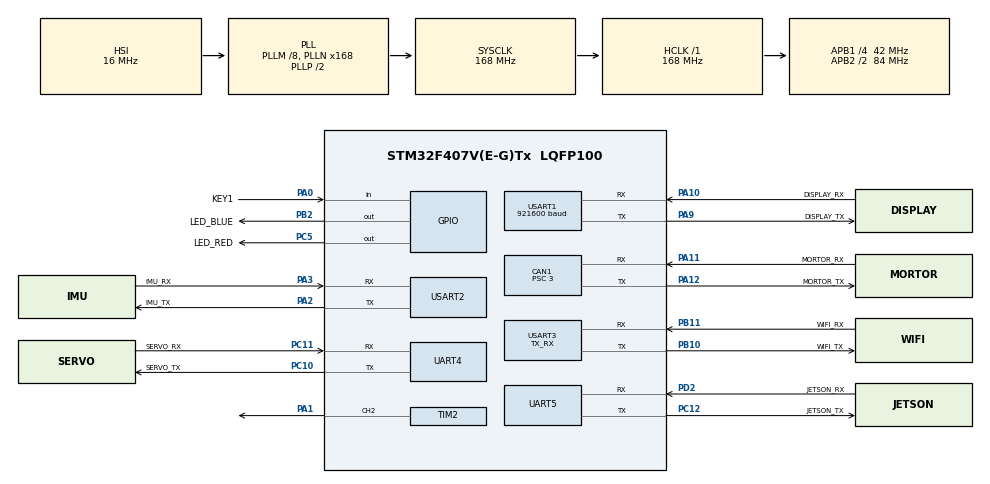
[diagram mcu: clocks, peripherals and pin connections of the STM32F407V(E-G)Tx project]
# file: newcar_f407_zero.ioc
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CAN1.ABOM=DISABLE
CAN1.AWUM=ENABLE
CAN1.BS1=CAN_BS1_7TQ
CAN1.BS2=CAN_BS2_6TQ
CAN1.CalculateBaudRate=1000000
CAN1.CalculateTimeBit=1000
CAN1.CalculateTimeQuantum=71.42857142857143
CAN1.NART=DISABLE
CAN1.Prescaler=3
Dma.MEMTOMEM.0.Direction=DMA_MEMORY_TO_MEMORY
Dma.MEMTOMEM.0.FIFOMode=DMA_FIFOMODE_ENABLE
Dma.MEMTOMEM.0.FIFOThreshold=DMA_FIFO_THRESHOLD_FULL
Dma.MEMTOMEM.0.Instance=DMA2_Stream0
Dma.MEMTOMEM.0.MemBurst=DMA_MBURST_SINGLE
Dma.MEMTOMEM.0.MemDataAlignment=DMA_MDATAALIGN_BYTE
Dma.MEMTOMEM.0.MemInc=DMA_MINC_ENABLE
Dma.MEMTOMEM.0.Mode=DMA_NORMAL
Dma.MEMTOMEM.0.PeriphBurst=DMA_PBURST_SINGLE
Dma.MEMTOMEM.0.PeriphDataAlignment=DMA_PDATAALIGN_BYTE
Dma.MEMTOMEM.0.PeriphInc=DMA_PINC_ENABLE
Dma.MEMTOMEM.0.Priority=DMA_PRIORITY_LOW
Dma.Request0=MEMTOMEM
Dma.Request1=USART1_TX
Dma.Request10=USART1_RX
Dma.Request2=USART2_RX
Dma.Request3=USART2_TX
Dma.Request4=UART4_RX
Dma.Request5=UART4_TX
Dma.Request6=UART5_RX
Dma.Request7=UART5_TX
Dma.Request8=USART3_RX
Dma.Request9=USART3_TX
Dma.UART4_RX.4.Direction=DMA_PERIPH_TO_MEMORY
Dma.UART4_RX.4.FIFOMode=DMA_FIFOMODE_ENABLE
Dma.UART4_RX.4.FIFOThreshold=DMA_FIFO_THRESHOLD_FULL
Dma.UART4_RX.4.Instance=DMA1_Stream2
Dma.UART4_RX.4.MemBurst=DMA_MBURST_SINGLE
Dma.UART4_RX.4.MemDataAlignment=DMA_MDATAALIGN_BYTE
Dma.UART4_RX.4.MemInc=DMA_MINC_ENABLE
Dma.UART4_RX.4.Mode=DMA_NORMAL
Dma.UART4_RX.4.PeriphBurst=DMA_PBURST_SINGLE
Dma.UART4_RX.4.PeriphDataAlignment=DMA_PDATAALIGN_BYTE
Dma.UART4_RX.4.PeriphInc=DMA_PINC_DISABLE
Dma.UART4_RX.4.Priority=DMA_PRIORITY_LOW
Dma.UART4_TX.5.Direction=DMA_MEMORY_TO_PERIPH
Dma.UART4_TX.5.FIFOMode=DMA_FIFOMODE_ENABLE
Dma.UART4_TX.5.FIFOThreshold=DMA_FIFO_THRESHOLD_FULL
Dma.UART4_TX.5.Instance=DMA1_Stream4
Dma.UART4_TX.5.MemBurst=DMA_MBURST_SINGLE
Dma.UART4_TX.5.MemDataAlignment=DMA_MDATAALIGN_BYTE
Dma.UART4_TX.5.MemInc=DMA_MINC_ENABLE
Dma.UART4_TX.5.Mode=DMA_NORMAL
Dma.UART4_TX.5.PeriphBurst=DMA_PBURST_SINGLE
Dma.UART4_TX.5.PeriphDataAlignment=DMA_PDATAALIGN_BYTE
Dma.UART4_TX.5.PeriphInc=DMA_PINC_DISABLE
Dma.UART4_TX.5.Priority=DMA_PRIORITY_LOW
Dma.UART5_RX.6.Direction=DMA_PERIPH_TO_MEMORY
Dma.UART5_RX.6.FIFOMode=DMA_FIFOMODE_ENABLE
Dma.UART5_RX.6.FIFOThreshold=DMA_FIFO_THRESHOLD_FULL
Dma.UART5_RX.6.Instance=DMA1_Stream0
Dma.UART5_RX.6.MemBurst=DMA_MBURST_SINGLE
Dma.UART5_RX.6.MemDataAlignment=DMA_MDATAALIGN_BYTE
Dma.UART5_RX.6.MemInc=DMA_MINC_ENABLE
Dma.UART5_RX.6.Mode=DMA_NORMAL
Dma.UART5_RX.6.PeriphBurst=DMA_PBURST_SINGLE
Dma.UART5_RX.6.PeriphDataAlignment=DMA_PDATAALIGN_BYTE
Dma.UART5_RX.6.PeriphInc=DMA_PINC_DISABLE
Dma.UART5_RX.6.Priority=DMA_PRIORITY_VERY_HIGH
Dma.UART5_TX.7.Direction=DMA_MEMORY_TO_PERIPH
Dma.UART5_TX.7.FIFOMode=DMA_FIFOMODE_ENABLE
Dma.UART5_TX.7.FIFOThreshold=DMA_FIFO_THRESHOLD_FULL
Dma.UART5_TX.7.Instance=DMA1_Stream7
Dma.UART5_TX.7.MemBurst=DMA_MBURST_SINGLE
Dma.UART5_TX.7.MemDataAlignment=DMA_MDATAALIGN_BYTE
Dma.UART5_TX.7.MemInc=DMA_MINC_ENABLE
Dma.UART5_TX.7.Mode=DMA_NORMAL
Dma.UART5_TX.7.PeriphBurst=DMA_PBURST_SINGLE
Dma.UART5_TX.7.PeriphDataAlignment=DMA_PDATAALIGN_BYTE
Dma.UART5_TX.7.PeriphInc=DMA_PINC_DISABLE
Dma.UART5_TX.7.Priority=DMA_PRIORITY_VERY_HIGH
Dma.USART1_RX.10.Direction=DMA_PERIPH_TO_MEMORY
Dma.USART1_RX.10.FIFOMode=DMA_FIFOMODE_ENABLE
Dma.USART1_RX.10.FIFOThreshold=DMA_FIFO_THRESHOLD_FULL
Dma.USART1_RX.10.Instance=DMA2_Stream2
Dma.USART1_RX.10.MemBurst=DMA_MBURST_SINGLE
Dma.USART1_RX.10.MemDataAlignment=DMA_MDATAALIGN_BYTE
Dma.USART1_RX.10.MemInc=DMA_MINC_ENABLE
Dma.USART1_RX.10.Mode=DMA_NORMAL
Dma.USART1_RX.10.PeriphBurst=DMA_PBURST_SINGLE
Dma.USART1_RX.10.PeriphDataAlignment=DMA_PDATAALIGN_BYTE
Dma.USART1_RX.10.PeriphInc=DMA_PINC_DISABLE
Dma.USART1_RX.10.Priority=DMA_PRIORITY_VERY_HIGH
Dma.USART1_TX.1.Direction=DMA_MEMORY_TO_PERIPH
Dma.USART1_TX.1.FIFOMode=DMA_FIFOMODE_ENABLE
Dma.USART1_TX.1.FIFOThreshold=DMA_FIFO_THRESHOLD_FULL
Dma.USART1_TX.1.Instance=DMA2_Stream7
Dma.USART1_TX.1.MemBurst=DMA_MBURST_SINGLE
Dma.USART1_TX.1.MemDataAlignment=DMA_MDATAALIGN_BYTE
Dma.USART1_TX.1.MemInc=DMA_MINC_ENABLE
Dma.USART1_TX.1.Mode=DMA_NORMAL
Dma.USART1_TX.1.PeriphBurst=DMA_PBURST_SINGLE
Dma.USART1_TX.1.PeriphDataAlignment=DMA_PDATAALIGN_BYTE
Dma.USART1_TX.1.PeriphInc=DMA_PINC_DISABLE
Dma.USART1_TX.1.Priority=DMA_PRIORITY_VERY_HIGH
Dma.USART2_RX.2.Direction=DMA_PERIPH_TO_MEMORY
Dma.USART2_RX.2.FIFOMode=DMA_FIFOMODE_ENABLE
Dma.USART2_RX.2.FIFOThreshold=DMA_FIFO_THRESHOLD_FULL
Dma.USART2_RX.2.Instance=DMA1_Stream5
Dma.USART2_RX.2.MemBurst=DMA_MBURST_SINGLE
Dma.USART2_RX.2.MemDataAlignment=DMA_MDATAALIGN_BYTE
Dma.USART2_RX.2.MemInc=DMA_MINC_ENABLE
Dma.USART2_RX.2.Mode=DMA_NORMAL
Dma.USART2_RX.2.PeriphBurst=DMA_PBURST_SINGLE
Dma.USART2_RX.2.PeriphDataAlignment=DMA_PDATAALIGN_BYTE
Dma.USART2_RX.2.PeriphInc=DMA_PINC_DISABLE
Dma.USART2_RX.2.Priority=DMA_PRIORITY_LOW
Dma.USART2_TX.3.Direction=DMA_MEMORY_TO_PERIPH
Dma.USART2_TX.3.FIFOMode=DMA_FIFOMODE_ENABLE
Dma.USART2_TX.3.FIFOThreshold=DMA_FIFO_THRESHOLD_FULL
Dma.USART2_TX.3.Instance=DMA1_Stream6
Dma.USART2_TX.3.MemBurst=DMA_MBURST_SINGLE
Dma.USART2_TX.3.MemDataAlignment=DMA_MDATAALIGN_BYTE
Dma.USART2_TX.3.MemInc=DMA_MINC_ENABLE
Dma.USART2_TX.3.Mode=DMA_NORMAL
Dma.USART2_TX.3.PeriphBurst=DMA_PBURST_SINGLE
Dma.USART2_TX.3.PeriphDataAlignment=DMA_PDATAALIGN_BYTE
Dma.USART2_TX.3.PeriphInc=DMA_PINC_DISABLE
Dma.USART2_TX.3.Priority=DMA_PRIORITY_LOW
Dma.USART3_RX.8.Direction=DMA_PERIPH_TO_MEMORY
Dma.USART3_RX.8.FIFOMode=DMA_FIFOMODE_DISABLE
Dma.USART3_RX.8.Instance=DMA1_Stream1
Dma.USART3_RX.8.MemDataAlignment=DMA_MDATAALIGN_BYTE
Dma.USART3_RX.8.MemInc=DMA_MINC_ENABLE
Dma.USART3_RX.8.Mode=DMA_NORMAL
Dma.USART3_RX.8.PeriphDataAlignment=DMA_PDATAALIGN_BYTE
Dma.USART3_RX.8.PeriphInc=DMA_PINC_DISABLE
Dma.USART3_RX.8.Priority=DMA_PRIORITY_LOW
Dma.USART3_TX.9.Direction=DMA_MEMORY_TO_PERIPH
Dma.USART3_TX.9.FIFOMode=DMA_FIFOMODE_DISABLE
Dma.USART3_TX.9.Instance=DMA1_Stream3
Dma.USART3_TX.9.MemDataAlignment=DMA_MDATAALIGN_BYTE
Dma.USART3_TX.9.MemInc=DMA_MINC_ENABLE
Dma.USART3_TX.9.Mode=DMA_NORMAL
Dma.USART3_TX.9.PeriphDataAlignment=DMA_PDATAALIGN_BYTE
Dma.USART3_TX.9.PeriphInc=DMA_PINC_DISABLE
Dma.USART3_TX.9.Priority=DMA_PRIORITY_HIGH
IWDG.Prescaler=IWDG_PRESCALER_256
IWDG.Reload=625-1
Mcu.Family=STM32F4
Mcu.Name=STM32F407V(E-G)Tx
Mcu.Package=LQFP100
NVIC.CAN1_RX0_IRQn=true\:0\:0\:false\:false\:true\:true\:true\:true
NVIC.DMA1_Stream0_IRQn=true\:0\:0\:false\:false\:true\:false\:true\:true
NVIC.DMA1_Stream1_IRQn=true\:0\:0\:false\:false\:true\:false\:true\:true
NVIC.DMA1_Stream2_IRQn=true\:0\:0\:false\:false\:true\:false\:true\:true
NVIC.DMA1_Stream3_IRQn=true\:0\:0\:false\:false\:true\:false\:true\:true
NVIC.DMA1_Stream4_IRQn=true\:0\:0\:false\:false\:true\:false\:true\:true
NVIC.DMA1_Stream5_IRQn=true\:0\:0\:false\:false\:true\:false\:true\:true
NVIC.DMA1_Stream6_IRQn=true\:0\:0\:false\:false\:true\:false\:true\:true
NVIC.DMA1_Stream7_IRQn=true\:0\:0\:false\:false\:true\:false\:true\:true
NVIC.DMA2_Stream2_IRQn=true\:0\:0\:false\:false\:true\:false\:true\:true
NVIC.DMA2_Stream7_IRQn=true\:0\:0\:false\:false\:true\:false\:true\:true
NVIC.PriorityGroup=NVIC_PRIORITYGROUP_4
NVIC.TIM6_DAC_IRQn=true\:0\:0\:false\:false\:true\:true\:true\:true
NVIC.UART4_IRQn=true\:0\:0\:false\:false\:true\:false\:true\:true
NVIC.UART5_IRQn=true\:0\:0\:false\:false\:true\:true\:true\:true
NVIC.USART1_IRQn=true\:0\:0\:false\:false\:true\:false\:true\:true
NVIC.USART2_IRQn=true\:0\:0\:false\:false\:true\:true\:true\:true
NVIC.USART3_IRQn=true\:0\:0\:false\:false\:true\:false\:true\:true
PA0-WKUP.GPIO_Label=KEY1
PA0-WKUP.GPIO_PuPd=GPIO_PULLDOWN
PA0-WKUP.Signal=GPIO_Input
PA1.Signal=S_TIM2_CH2
PA10.GPIO_Label=DISPLAY_RX
PA10.Mode=Asynchronous
PA10.Signal=USART1_RX
PA11.GPIO_Label=MORTOR_RX
PA11.Mode=CAN_Activate
PA11.Signal=CAN1_RX
PA12.GPIO_Label=MORTOR_TX
PA12.Mode=CAN_Activate
PA12.Signal=CAN1_TX
PA13.Mode=Serial_Wire
PA13.Signal=SYS_JTMS-SWDIO
PA14.Mode=Serial_Wire
PA14.Signal=SYS_JTCK-SWCLK
PA2.GPIO_Label=IMU_TX
PA2.Mode=Asynchronous
PA2.Signal=USART2_TX
PA3.GPIO_Label=IMU_RX
PA3.Mode=Asynchronous
PA3.Signal=USART2_RX
PA9.GPIO_Label=DISPLAY_TX
PA9.Mode=Asynchronous
PA9.Signal=USART1_TX
PB10.GPIO_Label=WIFI_TX
PB10.Mode=Asynchronous
PB10.Signal=USART3_TX
PB11.GPIO_Label=WIFI_RX
PB11.Mode=Asynchronous
PB11.Signal=USART3_RX
PB2.GPIO_Label=LED_BLUE
PB2.Signal=GPIO_Output
PC10.GPIO_Label=SERVO_TX
PC10.Mode=Asynchronous
PC10.Signal=UART4_TX
PC11.GPIO_Label=SERVO_RX
PC11.Mode=Asynchronous
PC11.Signal=UART4_RX
PC12.GPIO_Label=JETSON_TX
PC12.GPIO_PuPd=GPIO_PULLUP
PC12.Mode=Asynchronous
PC12.Signal=UART5_TX
PC5.GPIO_Label=LED_RED
PC5.Signal=GPIO_Output
PD2.GPIO_Label=JETSON_RX
PD2.GPIO_PuPd=GPIO_PULLUP
PD2.Mode=Asynchronous
PD2.Signal=UART5_RX
PH0-OSC_IN.Mode=HSE-External-Oscillator
PH0-OSC_IN.Signal=RCC_OSC_IN
PH1-OSC_OUT.Mode=HSE-External-Oscillator
PH1-OSC_OUT.Signal=RCC_OSC_OUT
ProjectManager.HeapSize=0x200
ProjectManager.StackSize=0x400
ProjectManager.TargetToolchain=STM32CubeIDE
RCC.48MHZClocksFreq_Value=84000000
RCC.AHBFreq_Value=168000000
RCC.APB1CLKDivider=RCC_HCLK_DIV4
RCC.APB1Freq_Value=42000000
RCC.APB1TimFreq_Value=84000000
RCC.APB2CLKDivider=RCC_HCLK_DIV2
RCC.APB2Freq_Value=84000000
RCC.APB2TimFreq_Value=168000000
RCC.CortexFreq_Value=168000000
RCC.HCLKFreq_Value=168000000
RCC.HSE_VALUE=25000000
RCC.HSI_VALUE=16000000
RCC.LSE_VALUE=32768
RCC.PLLM=8
RCC.PLLN=168
RCC.SYSCLKFreq_VALUE=168000000
RCC.SYSCLKSource=RCC_SYSCLKSOURCE_PLLCLK
RCC.VCOOutputFreq_Value=336000000
SH.S_TIM2_CH2.0=TIM2_CH2,PWM Generation2 CH2
STMicroelectronics.X-CUBE-ALGOBUILD.1.4.0.LibraryCcDSPOoLibraryJjDSPOoLibrary=true
TIM2.Channel-PWM\ Generation2\ CH2=TIM_CHANNEL_2
TIM2.Period=1000
TIM2.Prescaler=84-1
TIM2.Pulse-PWM\ Generation2\ CH2=500
TIM6.AutoReloadPreload=TIM_AUTORELOAD_PRELOAD_ENABLE
TIM6.Period=9
TIM6.Prescaler=8399
UART4.VirtualMode=Asynchronous
UART5.VirtualMode=Asynchronous
USART1.BaudRate=921600
USART1.Mode=MODE_TX_RX
USART1.Parity=PARITY_NONE
USART1.StopBits=STOPBITS_1
USART1.VirtualMode=VM_ASYNC
USART1.WordLength=WORDLENGTH_8B
USART2.VirtualMode=VM_ASYNC
USART3.Mode=MODE_TX_RX
USART3.VirtualMode=VM_ASYNC
VP_IWDG_VS_IWDG.Mode=IWDG_Activate
VP_STMicroelectronics.X-CUBE-ALGOBUILD_VS_DSPOoLibraryJjLibrary_1.4.0_1.4.0.Mode=DSPOoLibraryJjLibrary
VP_TIM2_VS_ClockSourceINT.Mode=Internal
VP_TIM6_VS_ClockSourceINT.Mode=Enable_Timer
board=custom

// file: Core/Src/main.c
/* USER CODE BEGIN Header */
/**
 ******************************************************************************
 * @file           : main.c
 * @brief          : Main program body
 ******************************************************************************
 * @attention
 *
 * Copyright (c) 2025 STMicroelectronics.
 * All rights reserved.
 *
 * This software is licensed under terms that can be found in the LICENSE file
 * in the root directory of this software component.
 * If no LICENSE file comes with this software, it is provided AS-IS.
 *
 ******************************************************************************
 */
/* USER CODE END Header */
#include "main.h"
#include "can.h"
#include "dma.h"
#include "gpio.h"
#include "iwdg.h"
#include "tim.h"
#include "usart.h"

/* USER CODE BEGIN Includes */
// #include "2_Device/Motor/Motor_ZDT42/Emm_V5.h"
#include "2_Device/Motor/Motor_ZDT42/dvc_zdt_x42.h"
#include "2_Device/Vofa/dvc_vofa.h"
#include "4_Task/task_config.h"
#include "arm_math.h"
/* USER CODE END Includes */

/* USER CODE BEGIN PV */
bool init_finished = false;

/* USER CODE END PV */

void SystemClock_Config(void);

int main(void)
{

    /* MCU Configuration--------------------------------------------------------*/

    /* Reset of all peripherals, Initializes the Flash interface and the Systick. */
    HAL_Init();

    /* Configure the system clock */
    SystemClock_Config();

    /* Initialize all configured peripherals */
    MX_GPIO_Init();
    MX_DMA_Init();
    MX_CAN1_Init();
    MX_UART4_Init();
    MX_USART1_UART_Init();
    MX_USART2_UART_Init();
    MX_USART3_UART_Init();
    MX_IWDG_Init();
    MX_UART5_Init();
    MX_TIM6_Init();
    MX_TIM2_Init();
    /* USER CODE BEGIN 2 */

    init_finished = true;
    Task_InitAll();

    /* USER CODE END 2 */

    /* Infinite loop */
    /* USER CODE BEGIN WHILE */
    while (1)
    {
        Task_RunAll();

        /* USER CODE END WHILE */

    }
}

void SystemClock_Config(void)
{
    RCC_OscInitTypeDef RCC_OscInitStruct = {0};
    RCC_ClkInitTypeDef RCC_ClkInitStruct = {0};

    /** Configure the main internal regulator output voltage
     */
    __HAL_RCC_PWR_CLK_ENABLE();
    __HAL_PWR_VOLTAGESCALING_CONFIG(PWR_REGULATOR_VOLTAGE_SCALE1);

    /** Initializes the RCC Oscillators according to the specified parameters
     * in the RCC_OscInitTypeDef structure.
     */
    RCC_OscInitStruct.OscillatorType      = RCC_OSCILLATORTYPE_HSI | RCC_OSCILLATORTYPE_LSI;
    RCC_OscInitStruct.HSIState            = RCC_HSI_ON;
    RCC_OscInitStruct.HSICalibrationValue = RCC_HSICALIBRATION_DEFAULT;
    RCC_OscInitStruct.LSIState            = RCC_LSI_ON;
    RCC_OscInitStruct.PLL.PLLState        = RCC_PLL_ON;
    RCC_OscInitStruct.PLL.PLLSource       = RCC_PLLSOURCE_HSI;
    RCC_OscInitStruct.PLL.PLLM            = 8;
    RCC_OscInitStruct.PLL.PLLN            = 168;
    RCC_OscInitStruct.PLL.PLLP            = RCC_PLLP_DIV2;
    RCC_OscInitStruct.PLL.PLLQ            = 4;
    if (HAL_RCC_OscConfig(&RCC_OscInitStruct) != HAL_OK)
    {
        Error_Handler();
    }

    /** Initializes the CPU, AHB and APB buses clocks
     */
    RCC_ClkInitStruct.ClockType = RCC_CLOCKTYPE_HCLK | RCC_CLOCKTYPE_SYSCLK | RCC_CLOCKTYPE_PCLK1 | RCC_CLOCKTYPE_PCLK2;
    RCC_ClkInitStruct.SYSCLKSource   = RCC_SYSCLKSOURCE_PLLCLK;
    RCC_ClkInitStruct.AHBCLKDivider  = RCC_SYSCLK_DIV1;
    RCC_ClkInitStruct.APB1CLKDivider = RCC_HCLK_DIV4;
    RCC_ClkInitStruct.APB2CLKDivider = RCC_HCLK_DIV2;

    if (HAL_RCC_ClockConfig(&RCC_ClkInitStruct, FLASH_LATENCY_5) != HAL_OK)
    {
        Error_Handler();
    }
}

void Error_Handler(void)
{
    /* USER CODE BEGIN Error_Handler_Debug */
    /* User can add his own implementation to report the HAL error return state */
    __disable_irq();
    while (1)
    {}
    /* USER CODE END Error_Handler_Debug */
}
